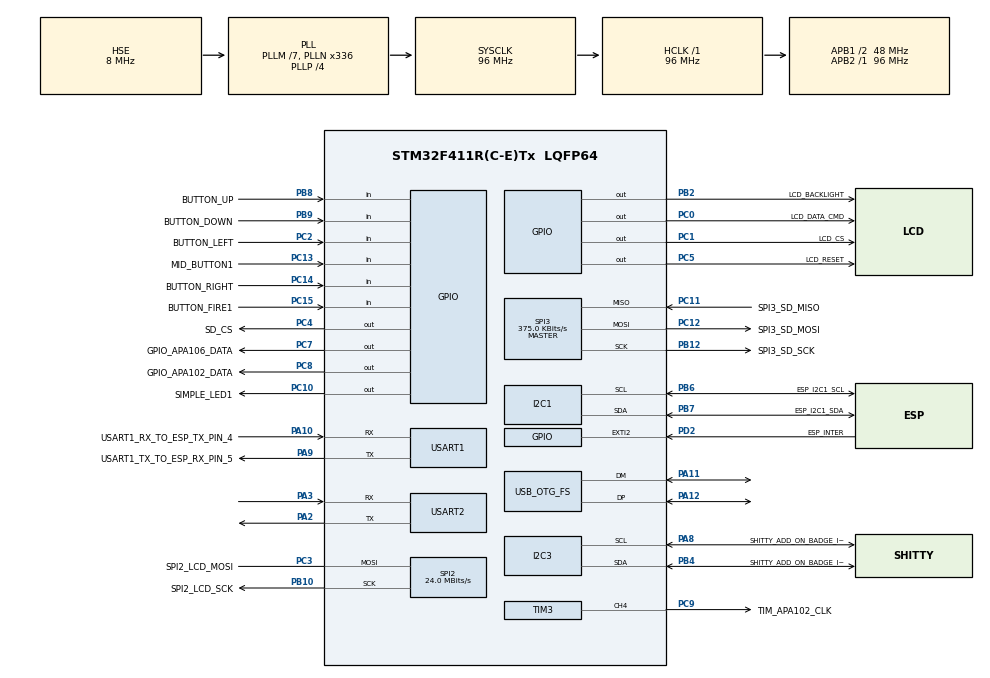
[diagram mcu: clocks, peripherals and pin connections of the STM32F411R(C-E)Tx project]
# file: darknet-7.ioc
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Dma.MEMTOMEM.3.Direction=DMA_MEMORY_TO_MEMORY
Dma.MEMTOMEM.3.FIFOMode=DMA_FIFOMODE_ENABLE
Dma.MEMTOMEM.3.FIFOThreshold=DMA_FIFO_THRESHOLD_FULL
Dma.MEMTOMEM.3.Instance=DMA2_Stream0
Dma.MEMTOMEM.3.MemBurst=DMA_MBURST_SINGLE
Dma.MEMTOMEM.3.MemDataAlignment=DMA_MDATAALIGN_BYTE
Dma.MEMTOMEM.3.MemInc=DMA_MINC_ENABLE
Dma.MEMTOMEM.3.Mode=DMA_NORMAL
Dma.MEMTOMEM.3.PeriphBurst=DMA_PBURST_SINGLE
Dma.MEMTOMEM.3.PeriphDataAlignment=DMA_PDATAALIGN_BYTE
Dma.MEMTOMEM.3.PeriphInc=DMA_PINC_ENABLE
Dma.MEMTOMEM.3.Priority=DMA_PRIORITY_MEDIUM
Dma.Request0=SPI3_RX
Dma.Request1=SPI3_TX
Dma.Request2=SPI2_TX
Dma.Request3=MEMTOMEM
Dma.SPI2_TX.2.Direction=DMA_MEMORY_TO_PERIPH
Dma.SPI2_TX.2.FIFOMode=DMA_FIFOMODE_DISABLE
Dma.SPI2_TX.2.Instance=DMA1_Stream4
Dma.SPI2_TX.2.MemDataAlignment=DMA_MDATAALIGN_BYTE
Dma.SPI2_TX.2.MemInc=DMA_MINC_ENABLE
Dma.SPI2_TX.2.Mode=DMA_NORMAL
Dma.SPI2_TX.2.PeriphDataAlignment=DMA_PDATAALIGN_BYTE
Dma.SPI2_TX.2.PeriphInc=DMA_PINC_DISABLE
Dma.SPI2_TX.2.Priority=DMA_PRIORITY_MEDIUM
Dma.SPI3_RX.0.Direction=DMA_PERIPH_TO_MEMORY
Dma.SPI3_RX.0.FIFOMode=DMA_FIFOMODE_DISABLE
Dma.SPI3_RX.0.Instance=DMA1_Stream0
Dma.SPI3_RX.0.MemDataAlignment=DMA_MDATAALIGN_BYTE
Dma.SPI3_RX.0.MemInc=DMA_MINC_ENABLE
Dma.SPI3_RX.0.Mode=DMA_NORMAL
Dma.SPI3_RX.0.PeriphDataAlignment=DMA_PDATAALIGN_BYTE
Dma.SPI3_RX.0.PeriphInc=DMA_PINC_DISABLE
Dma.SPI3_RX.0.Priority=DMA_PRIORITY_MEDIUM
Dma.SPI3_TX.1.Direction=DMA_MEMORY_TO_PERIPH
Dma.SPI3_TX.1.FIFOMode=DMA_FIFOMODE_DISABLE
Dma.SPI3_TX.1.Instance=DMA1_Stream5
Dma.SPI3_TX.1.MemDataAlignment=DMA_MDATAALIGN_BYTE
Dma.SPI3_TX.1.MemInc=DMA_MINC_ENABLE
Dma.SPI3_TX.1.Mode=DMA_NORMAL
Dma.SPI3_TX.1.PeriphDataAlignment=DMA_PDATAALIGN_BYTE
Dma.SPI3_TX.1.PeriphInc=DMA_PINC_DISABLE
Dma.SPI3_TX.1.Priority=DMA_PRIORITY_MEDIUM
FATFS._FS_EXFAT=1
FATFS._USE_LFN=2
Mcu.Family=STM32F4
Mcu.Name=STM32F411R(C-E)Tx
Mcu.Package=LQFP64
NVIC.DMA1_Stream0_IRQn=true\:0\:0\:false\:false\:true\:false
NVIC.DMA1_Stream4_IRQn=true\:0\:0\:false\:false\:true\:false
NVIC.DMA1_Stream5_IRQn=true\:0\:0\:false\:false\:true\:false
NVIC.EXTI2_IRQn=true\:0\:0\:false\:false\:true\:true
NVIC.OTG_FS_IRQn=true\:0\:0\:false\:false\:true\:false
NVIC.PriorityGroup=NVIC_PRIORITYGROUP_4
NVIC.USART1_IRQn=true\:0\:0\:false\:false\:true\:true
PA10.GPIO_Label=USART1_RX_TO_ESP_TX_PIN_4
PA10.Mode=Asynchronous
PA10.Signal=USART1_RX
PA11.Mode=Device_Only
PA11.Signal=USB_OTG_FS_DM
PA12.Mode=Device_Only
PA12.Signal=USB_OTG_FS_DP
PA13.Mode=Serial_Wire
PA13.Signal=SYS_JTMS-SWDIO
PA14.Mode=Serial_Wire
PA14.Signal=SYS_JTCK-SWCLK
PA2.Mode=Asynchronous
PA2.Signal=USART2_TX
PA3.Mode=Asynchronous
PA3.Signal=USART2_RX
PA8.GPIO_Label=SHITTY_ADD_ON_BADGE_I2C_SCL
PA8.Mode=I2C
PA8.Signal=I2C3_SCL
PA9.GPIO_Label=USART1_TX_TO_ESP_RX_PIN_5
PA9.Mode=Asynchronous
PA9.Signal=USART1_TX
PB10.GPIO_Label=SPI2_LCD_SCK
PB10.Mode=Simplex_Bidirectional_Master
PB10.Signal=SPI2_SCK
PB12.GPIO_Label=SPI3_SD_SCK
PB12.Mode=Full_Duplex_Master
PB12.Signal=SPI3_SCK
PB2.GPIO_Label=LCD_BACKLIGHT
PB2.Signal=GPIO_Output
PB4.GPIO_Label=SHITTY_ADD_ON_BADGE_I2C_SDA
PB4.Mode=I2C
PB4.Signal=I2C3_SDA
PB6.GPIO_Label=ESP_I2C1_SCL
PB6.Mode=I2C
PB6.Signal=I2C1_SCL
PB7.GPIO_Label=ESP_I2C1_SDA
PB7.Mode=I2C
PB7.Signal=I2C1_SDA
PB8.GPIO_Label=BUTTON_UP
PB8.Signal=GPIO_Input
PB9.GPIO_Label=BUTTON_DOWN
PB9.Signal=GPIO_Input
PC0.GPIO_Label=LCD_DATA_CMD
PC0.Signal=GPIO_Output
PC1.GPIO_Label=LCD_CS
PC1.Signal=GPIO_Output
PC10.GPIO_Label=SIMPLE_LED1
PC10.Signal=GPIO_Output
PC11.GPIO_Label=SPI3_SD_MISO
PC11.Mode=Full_Duplex_Master
PC11.Signal=SPI3_MISO
PC12.GPIO_Label=SPI3_SD_MOSI
PC12.Mode=Full_Duplex_Master
PC12.Signal=SPI3_MOSI
PC13-ANTI_TAMP.GPIO_Label=MID_BUTTON1
PC13-ANTI_TAMP.Signal=GPIO_Input
PC14-OSC32_IN.GPIO_Label=BUTTON_RIGHT
PC14-OSC32_IN.Signal=GPIO_Input
PC15-OSC32_OUT.GPIO_Label=BUTTON_FIRE1
PC15-OSC32_OUT.Signal=GPIO_Input
PC2.GPIO_Label=BUTTON_LEFT
PC2.Signal=GPIO_Input
PC3.GPIO_Label=SPI2_LCD_MOSI
PC3.Mode=Simplex_Bidirectional_Master
PC3.Signal=SPI2_MOSI
PC4.GPIO_Label=SD_CS
PC4.Signal=GPIO_Output
PC5.GPIO_Label=LCD_RESET
PC5.Signal=GPIO_Output
PC7.GPIO_Label=GPIO_APA106_DATA
PC7.GPIO_Speed=GPIO_SPEED_FREQ_MEDIUM
PC7.Signal=GPIO_Output
PC8.GPIO_Label=GPIO_APA102_DATA
PC8.Signal=GPIO_Output
PC9.GPIO_Label=TIM_APA102_CLK
PC9.GPIO_PuPd=GPIO_PULLUP
PC9.GPIO_Speed=GPIO_SPEED_FREQ_HIGH
PC9.Signal=S_TIM3_CH4
PD2.GPIO_Label=ESP_INTER
PD2.Signal=GPXTI2
PH0\ -\ OSC_IN.Mode=HSE-External-Oscillator
PH0\ -\ OSC_IN.Signal=RCC_OSC_IN
PH1\ -\ OSC_OUT.Mode=HSE-External-Oscillator
PH1\ -\ OSC_OUT.Signal=RCC_OSC_OUT
ProjectManager.HeapSize=0x200
ProjectManager.StackSize=0x400
ProjectManager.TargetToolchain=SW4STM32
RCC.48MHZClocksFreq_Value=48000000.00000001
RCC.AHBFreq_Value=96000000.00000001
RCC.APB1CLKDivider=RCC_HCLK_DIV2
RCC.APB1Freq_Value=48000000.00000001
RCC.APB1TimFreq_Value=96000000.00000001
RCC.APB2Freq_Value=96000000.00000001
RCC.APB2TimFreq_Value=96000000.00000001
RCC.CortexFreq_Value=96000000.00000001
RCC.HCLKFreq_Value=96000000.00000001
RCC.HSE_VALUE=8000000
RCC.HSI_VALUE=16000000
RCC.LSE_VALUE=32768
RCC.PLLM=7
RCC.PLLN=336
RCC.PLLP=RCC_PLLP_DIV4
RCC.PLLQ=8
RCC.SYSCLKFreq_VALUE=96000000.00000001
RCC.SYSCLKSource=RCC_SYSCLKSOURCE_PLLCLK
RCC.VCOOutputFreq_Value=384000000.00000006
SH.S_TIM3_CH4.0=TIM3_CH4,PWM Generation4 CH4
SPI2.CalculateBaudRate=24.0 MBits/s
SPI2.Direction=SPI_DIRECTION_1LINE
SPI2.Mode=SPI_MODE_MASTER
SPI2.VirtualType=VM_MASTER
SPI3.BaudRatePrescaler=SPI_BAUDRATEPRESCALER_128
SPI3.CalculateBaudRate=375.0 KBits/s
SPI3.Direction=SPI_DIRECTION_2LINES
SPI3.Mode=SPI_MODE_MASTER
SPI3.VirtualType=VM_MASTER
TIM3.Channel-PWM\ Generation4\ CH4=TIM_CHANNEL_4
USART1.VirtualMode=VM_ASYNC
USART2.VirtualMode=VM_ASYNC
USB_DEVICE.CLASS_NAME_FS=CDC
USB_DEVICE.VirtualMode=Cdc
USB_DEVICE.VirtualModeFS=Cdc_FS
USB_OTG_FS.VirtualMode=Device_Only
VP_FATFS_VS_Generic.Mode=User_defined
VP_TIM3_VS_ClockSourceINT.Mode=Internal
VP_USB_DEVICE_VS_USB_DEVICE_CDC_FS.Mode=CDC_FS
board=darknet-7

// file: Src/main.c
/**
  ******************************************************************************
  * @file           : main.c
  * @brief          : Main program body
  ******************************************************************************
  * This notice applies to any and all portions of this file
  * that are not between comment pairs USER CODE BEGIN and
  * USER CODE END. Other portions of this file, whether
  * inserted by the user or by software development tools
  * are owned by their respective copyright owners.
  *
  * Copyright (c) 2018 STMicroelectronics International N.V.
  * All rights reserved.
  *
  * Redistribution and use in source and binary forms, with or without
  * modification, are permitted, provided that the following conditions are met:
  *
  * 1. Redistribution of source code must retain the above copyright notice,
  *    this list of conditions and the following disclaimer.
  * 2. Redistributions in binary form must reproduce the above copyright notice,
  *    this list of conditions and the following disclaimer in the documentation
  *    and/or other materials provided with the distribution.
  * 3. Neither the name of STMicroelectronics nor the names of other
  *    contributors to this software may be used to endorse or promote products
  *    derived from this software without specific written permission.
  * 4. This software, including modifications and/or derivative works of this
  *    software, must execute solely and exclusively on microcontroller or
  *    microprocessor devices manufactured by or for STMicroelectronics.
  * 5. Redistribution and use of this software other than as permitted under
  *    this license is void and will automatically terminate your rights under
  *    this license.
  *
  * THIS SOFTWARE IS PROVIDED BY STMICROELECTRONICS AND CONTRIBUTORS "AS IS"
  * AND ANY EXPRESS, IMPLIED OR STATUTORY WARRANTIES, INCLUDING, BUT NOT
  * LIMITED TO, THE IMPLIED WARRANTIES OF MERCHANTABILITY, FITNESS FOR A
  * PARTICULAR PURPOSE AND NON-INFRINGEMENT OF THIRD PARTY INTELLECTUAL PROPERTY
  * RIGHTS ARE DISCLAIMED TO THE FULLEST EXTENT PERMITTED BY LAW. IN NO EVENT
  * SHALL STMICROELECTRONICS OR CONTRIBUTORS BE LIABLE FOR ANY DIRECT, INDIRECT,
  * INCIDENTAL, SPECIAL, EXEMPLARY, OR CONSEQUENTIAL DAMAGES (INCLUDING, BUT NOT
  * LIMITED TO, PROCUREMENT OF SUBSTITUTE GOODS OR SERVICES; LOSS OF USE, DATA,
  * OR PROFITS; OR BUSINESS INTERRUPTION) HOWEVER CAUSED AND ON ANY THEORY OF
  * LIABILITY, WHETHER IN CONTRACT, STRICT LIABILITY, OR TORT (INCLUDING
  * NEGLIGENCE OR OTHERWISE) ARISING IN ANY WAY OUT OF THE USE OF THIS SOFTWARE,
  * EVEN IF ADVISED OF THE POSSIBILITY OF SUCH DAMAGE.
  *
  ******************************************************************************
  */
#include "main.h"
#include "stm32f4xx_hal.h"
#include "dma.h"
#include "fatfs.h"
#include "i2c.h"
#include "spi.h"
#include "tim.h"
#include "usart.h"
#include "usb_device.h"
#include "gpio.h"

/* USER CODE BEGIN Includes */
#include "darknet/init.h"
/* USER CODE END Includes */

/* USER CODE BEGIN PV */
/* Private variables ---------------------------------------------------------*/

/* USER CODE END PV */

void SystemClock_Config(void);

/* USER CODE BEGIN PFP */
/* Private function prototypes -----------------------------------------------*/

/* USER CODE END PFP */

int main(void)
{

  /* MCU Configuration----------------------------------------------------------*/

  /* Reset of all peripherals, Initializes the Flash interface and the Systick. */
  HAL_Init();

  /* Configure the system clock */
  SystemClock_Config();

  /* Initialize all configured peripherals */
  MX_GPIO_Init();
  MX_DMA_Init();
  MX_I2C1_Init();
  MX_SPI2_Init();
  MX_SPI3_Init();
  MX_USART1_UART_Init();
  MX_USB_DEVICE_Init();
  MX_USART2_UART_Init();
  MX_TIM3_Init();
  MX_I2C3_Init();
  MX_FATFS_Init();
  /* USER CODE BEGIN 2 */
  init();
  /* USER CODE END 2 */

  /* Infinite loop */
  while (1)
  {

  /* USER CODE BEGIN 3 */
	  runOnce();
  }
  /* USER CODE END 3 */

}

void SystemClock_Config(void)
{

  RCC_OscInitTypeDef RCC_OscInitStruct;
  RCC_ClkInitTypeDef RCC_ClkInitStruct;

    /**Configure the main internal regulator output voltage
    */
  __HAL_RCC_PWR_CLK_ENABLE();

  __HAL_PWR_VOLTAGESCALING_CONFIG(PWR_REGULATOR_VOLTAGE_SCALE1);

    /**Initializes the CPU, AHB and APB busses clocks
    */
  RCC_OscInitStruct.OscillatorType = RCC_OSCILLATORTYPE_HSE;
  RCC_OscInitStruct.HSEState = RCC_HSE_ON;
  RCC_OscInitStruct.PLL.PLLState = RCC_PLL_ON;
  RCC_OscInitStruct.PLL.PLLSource = RCC_PLLSOURCE_HSE;
  RCC_OscInitStruct.PLL.PLLM = 7;
  RCC_OscInitStruct.PLL.PLLN = 336;
  RCC_OscInitStruct.PLL.PLLP = RCC_PLLP_DIV4;
  RCC_OscInitStruct.PLL.PLLQ = 8;
  if (HAL_RCC_OscConfig(&RCC_OscInitStruct) != HAL_OK)
  {
    _Error_Handler(__FILE__, __LINE__);
  }

    /**Initializes the CPU, AHB and APB busses clocks
    */
  RCC_ClkInitStruct.ClockType = RCC_CLOCKTYPE_HCLK|RCC_CLOCKTYPE_SYSCLK
                              |RCC_CLOCKTYPE_PCLK1|RCC_CLOCKTYPE_PCLK2;
  RCC_ClkInitStruct.SYSCLKSource = RCC_SYSCLKSOURCE_PLLCLK;
  RCC_ClkInitStruct.AHBCLKDivider = RCC_SYSCLK_DIV1;
  RCC_ClkInitStruct.APB1CLKDivider = RCC_HCLK_DIV2;
  RCC_ClkInitStruct.APB2CLKDivider = RCC_HCLK_DIV1;

  if (HAL_RCC_ClockConfig(&RCC_ClkInitStruct, FLASH_LATENCY_3) != HAL_OK)
  {
    _Error_Handler(__FILE__, __LINE__);
  }

    /**Configure the Systick interrupt time
    */
  HAL_SYSTICK_Config(HAL_RCC_GetHCLKFreq()/1000);

    /**Configure the Systick
    */
  HAL_SYSTICK_CLKSourceConfig(SYSTICK_CLKSOURCE_HCLK);

  /* SysTick_IRQn interrupt configuration */
  HAL_NVIC_SetPriority(SysTick_IRQn, 0, 0);
}

void _Error_Handler(char *file, int line)
{
  while(1)
  {
  }
}

/************************ (C) COPYRIGHT STMicroelectronics *****END OF FILE****/
